# USB_USB_TRBB_53904000h register map
Vendor: Texas Instruments
Peripheral module from a debugger description file (folder AM261x).
Registers are 32-bit, read-write, reset 0x0 unless marked. A register's access mark holds for its fields unless they carry their own. Offsets are as the file gives them; lines under a group give offsets from that group; [hi:lo] are bit positions; {n}, {i} and the like mark numbered series; 'fields as' and 'values as' point back to an identical list; <NAME> marks a mode.

## USB_TRBB
0x00 USB_TRBB_PARAM_LO — This register indicates Buffer-Pointer-Low.
  [31:0] BPTRL — Buffer Pointer Low: Data buffer's base address pointer, lower 32 bits.Typically read-only for the USB controller's DMA [HW]. However, HW can be made to overwrite the pointer with an incoming [8-byte] SETUP packet, by setting the 64-bit pointer to its own address [i.e. that of PARAM_LO].
0x04 USB_TRBB_PARAM_HI — This register indicates Buffer-Pointer-High.
  [31:0] BPTRH — Buffer Pointer High: Data buffer's base address pointer, upper 32 bits.Typically read-only for the USB controller's DMA [HW]. However, HW can be made to overwrite the pointer with an incoming [8-byte] SETUP packet, by setting the 64-bit pointer to its own address [i.e. that of PARAM_LO].
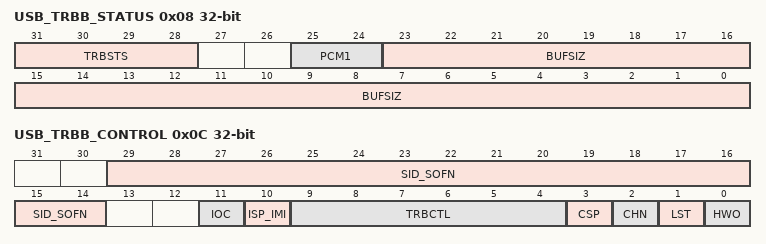
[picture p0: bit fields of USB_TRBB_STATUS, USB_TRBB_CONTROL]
0x08 USB_TRBB_STATUS — This regiaster indicates TRB Status, Packet Count and Buffer Size.
  [31:28] TRBSTS — TRB Status. Updated by HW transfer status information before releasing the TRB.
  [25:24] PCM1 — Packet Count Minus1:Total number of packets in the Buffer Descriptor, minus 1, for High-Speed, High Bandwidth isochronous IN endpoints, in an Isoc-First TRB.
  [23:0] BUFSIZ — Buffer Size. Remaining size [to be sent / which can be received] in TRB's data buffer, in bytes. Decremented by HW after data is transferred.
0x0C USB_TRBB_CONTROL access per field — This register indicates Transfer Control, Interrupt Control and Stream ID.
  [29:14] SID_SOFN rw — Stream ID / SOF Number. Stream-based bulk EP: The Stream ID of the transfer.Isochronous EP: [micro]frame number in which the last packet of the buffer was transmitted [debug].
  [11] IOC ro — Interrupt on Complete. Applicable only when LST=0, for a] IN EP or b] OUT EP when CSP=1.Read-only for the USB controller's DMA [HW].
  [10] ISP_IMI ro — Interrupt on Short Packet / Interrupt on Missed ISOC. Controls the generation of the XferInProgress event. Read-only for the USB controller's DMA [HW].
  [9:4] TRBCTL ro — TRB Control. Type of TRB.Read-only for the USB controller's DMA [HW].
  [3] CSP ro — Continue on Short Packet. Reaction of an OUT endpoint upon reception of a short packet.Read-only for the USB controller's DMA [HW].
  [2] CHN ro — Chain Buffers. Associates this TRB with the next in the same Buffer Descriptor. Always 0 in the last TRB of a Buffer Descriptor.Read-only for the USB controller's DMA [HW].
  [1] LST ro — Last TRB. Indicates the last TRB in a list, i.e. in a transfer for the endpoint / bulk-stream. Read-only for the USB controller's DMA [HW].
  [0] HWO rw — Hardware Owner. TRB ownership. Set to 1 by SW when creating the TRB. SW cannot modify the TRB again until cleared to 0 by HW. There are exceptions for short packets on OUT endpoints and Link TRBs.
